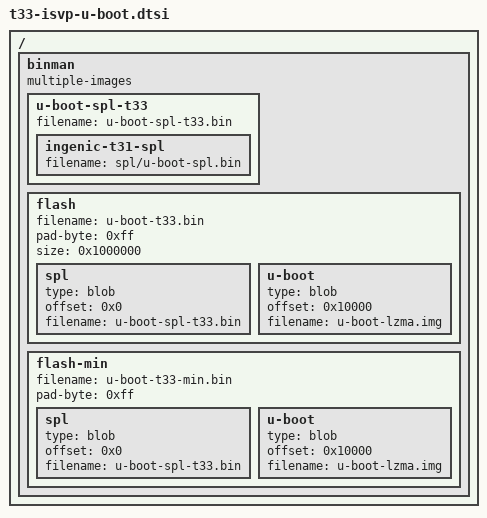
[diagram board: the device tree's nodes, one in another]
// SPDX-License-Identifier: GPL-2.0+
/*
 * Binman image description for the Ingenic ISVP-T33 SFC-NOR boot.
 *
 * The T33 mask ROM (and the QEMU ingenic-t33 model, which emulates
 * it) boots SPI-NOR by reading the 2 KiB SPL header at flash offset
 * 0: magic 0x03040506 (emitted by start.S), total image length at
 * byte 12. It then copies header+SPL and enters at offset 0x800.
 * The ingenic-t31-spl entry finalizes that header (CRC7 + length);
 * it is the T31 mask-ROM contract, shared verbatim by the T33
 * bootrom / QEMU model, so it is reused as-is.
 *
 *   u-boot-spl-t33.bin : SPL with the finalized boot header.
 *   u-boot-t33.bin     : 16 MB flash image - headered SPL at 0,
 *                        LZMA U-Boot at 0x10000, 0xff-padded.
 *   u-boot-t33-min.bin : same layout, trimmed to the last entry.
 */

/ {
	binman: binman {
		multiple-images;
	};
};

&binman {
	/* Standalone headered SPL (CRC7 + image length finalized). */
	u-boot-spl-t33 {
		filename = "u-boot-spl-t33.bin";

		ingenic-t31-spl {
			filename = "spl/u-boot-spl.bin";
		};
	};

	flash {
		filename = "u-boot-t33.bin";
		pad-byte = <0xff>;
		size = <0x1000000>;

		spl {
			type = "blob";
			offset = <0x0>;
			filename = "u-boot-spl-t33.bin";
		};

		/*
		 * LZMA-compressed U-Boot proper in a legacy mkimage
		 * header; the SPL parses the header and decompresses to
		 * CONFIG_TEXT_BASE.
		 */
		u-boot {
			type = "blob";
			offset = <0x10000>;
			filename = "u-boot-lzma.img";
		};
	};

	flash-min {
		filename = "u-boot-t33-min.bin";
		pad-byte = <0xff>;

		spl {
			type = "blob";
			offset = <0x0>;
			filename = "u-boot-spl-t33.bin";
		};

		u-boot {
			type = "blob";
			offset = <0x10000>;
			filename = "u-boot-lzma.img";
		};
	};
};
